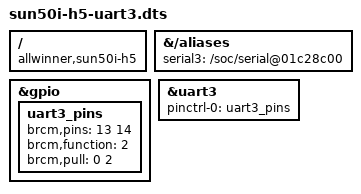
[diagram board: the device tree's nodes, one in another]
/dts-v1/;
/plugin/;

/ {
	compatible = "allwinner,sun50i-h5";

	fragment@0 {
		target-path = "/aliases";
		__overlay__ {
			serial3 = "/soc/serial@01c28c00";
		};
	};
	

	
	fragment@1 {
		target = <&gpio>;
		__overlay__ {
			uart3_pins: uart3_pins {
				brcm,pins = <13 14>;
				brcm,function = <2>; /* alt5 */
				brcm,pull = <0 2>;
			};
		};
	};
	fragment@2 {
		target = <&uart3>;
		 __overlay__ {
			pinctrl-names = "default";
			pinctrl-0 = <&uart3_pins>;
			status = "okay";
		};
	};
};
